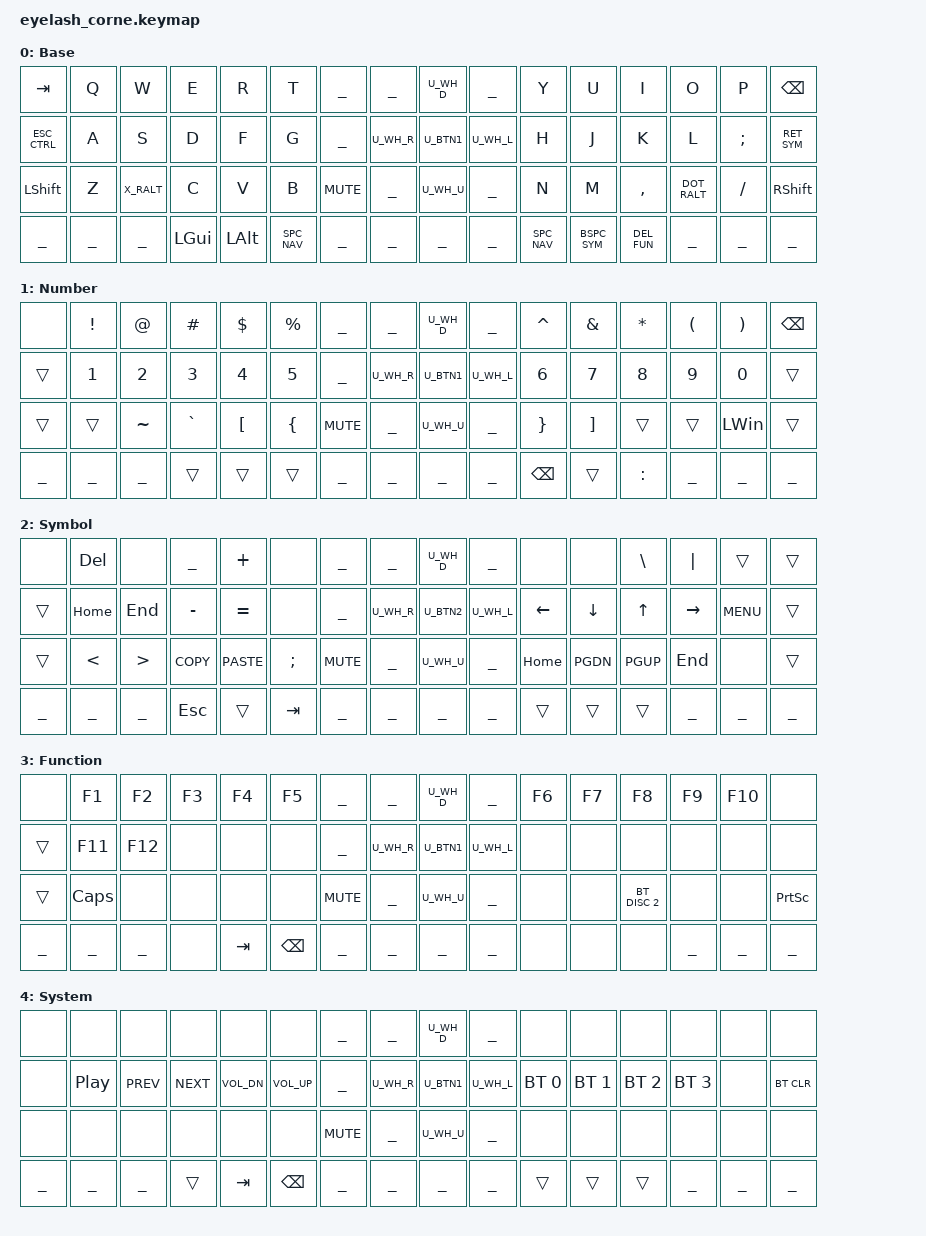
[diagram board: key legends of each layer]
// Example config: https://github.com/manna-harbour/miryoku_zmk?tab=readme-ov-file#example-config-file

#define MIRYOKU_ALPHAS_QWERTY
#define MIRYOKU_TAP_QWERTY
#define MIRYOKU_EXTRA_COLEMAK
#define MIRYOKU_NAV_VI

#define XXX &none

#define ENC_VOL  &inc_dec_kp C_VOLUME_UP C_VOLUME_DOWN
#define CTRL_ESC &mt LEFT_CONTROL ESC

// Make rotary decoder button to mute
// Make joystick to scroll in natural mode, button to click
//

#define MIRYOKU_CLIPBOARD_FUN
#define MIRYOKU_KLUDGE_MOUSEKEYSPR


// #include "../modules/miryoku/miryoku/miryoku.dtsi"
// Adding sensor bindings to the layers for the decoder
//
#include <behaviors.dtsi>
#include <behaviors/mouse_key_press.dtsi>
#include <behaviors/mouse_move.dtsi>
#include <behaviors/mouse_scroll.dtsi>
#include <dt-bindings/zmk/keys.h>
#include <dt-bindings/zmk/bt.h>
#include <dt-bindings/zmk/rgb.h>
#include <dt-bindings/zmk/outputs.h>
#include <dt-bindings/zmk/ext_power.h>

// Define my own miryoku layers that override the default ones
//

// Changes from original
//
// First left thumb -> LGUI instead of Media, Move media to a combo of both thumbs
// Second left thumb -> LALT instead of Nav/space
// Third left thumb -> Nav/space, mouse layer moved to combo
// Remove homerow mods from base layer (some are still in other layers, but not bothering right now)
// Swap semicolon/colon with apostrophe/doble-quote


// Adding an extra layer WIN
// miryoku defines 10 layers, with 0-based index, so next one is number 10
// Adds LALT on right thumb, for Mod+Alt combined modifier
#define U_WIN 10

// Load Miryoku logic
#include "../modules/miryoku/miryoku/miryoku.h"

#include <dt-bindings/zmk/mouse.h>

// empty key block, for better spacing
#define ___ 

// TODO what is LFUN
// TODO what is LBTN
// TODO once LBTN is decided, update Z_BTN, SLASH_BTN

#define LBASE 0
#define LSYM 1 // lower
#define LNAV 2 // raise
#define LFUN 3 // function
#define LSYS 4 // system

#define ESC_CTRL U_MT(LCTRL, ESC)
// #define Z_BTN U_LT(U_BUTTON, Z)
#define Z_BTN &kp Z
#define SLASH_BTN &kp SLASH
#define X_RALT U_MT(RALT, X)
#define DOT_RALT U_MT(RALT, DOT)
#define SPC_NAV U_LT(LNAV, SPACE)
#define BSPC_SYM U_LT(LSYM, BSPC)
#define DEL_FUN U_LT(LFUN, DEL)
#define RET_SYM U_LT(LSYM, RET)

#define BT_SEL_0 &bt BT_SEL 0
#define BT_SEL_1 &bt BT_SEL 1
#define BT_SEL_2 &bt BT_SEL 2
#define BT_SEL_3 &bt BT_SEL 3
#define BT_DIS_2 &bt BT_DISC 2
#define BT_CLEAR &bt BT_CLR

/ {
  keymap {
    compatible = "zmk,keymap";

    base {
      display-name = "Base";
      bindings = <
        &kp TAB   &kp Q    &kp W     &kp E       &kp R        &kp T        ___        ___    U_WH_D ___     &kp Y     &kp U      &kp I      &kp O     &kp P      &kp BSPC  \
        ESC_CTRL  &kp A    &kp S     &kp D       &kp F        &kp G        ___        U_WH_R U_BTN1 U_WH_L  &kp H     &kp J      &kp K      &kp L     &kp SEMI   RET_SYM   \
        &kp LSHFT Z_BTN    X_RALT    &kp C       &kp V        &kp B        &kp C_MUTE ___    U_WH_U ___     &kp N     &kp M      &kp COMMA  DOT_RALT  SLASH_BTN  &kp RSHFT \
        ___       ___      ___       &kp LGUI    &kp LALT     SPC_NAV      ___        ___    ___    ___     SPC_NAV   BSPC_SYM   DEL_FUN    ___       ___        ___       \
      >;
      sensor-bindings = < &inc_dec_kp C_VOLUME_UP C_VOLUME_DOWN >;
    };

    lower { display-name = "Number";
      bindings = <
        XXX       &kp EXCL &kp AT    &kp POUND   &kp DLLR     &kp PRCNT    ___        ___    U_WH_D ___     &kp CARET &kp AMPS   &kp ASTRK  &kp LPAR  &kp RPAR   &kp BSPC  \
        &trans    &kp N1   &kp N2    &kp N3      &kp N4       &kp N5       ___        U_WH_R U_BTN1 U_WH_L  &kp N6    &kp N7     &kp N8     &kp N9    &kp N0     &trans    \
        &trans    &trans   &kp TILDE &kp GRAVE   &kp LBKT     &kp LBRC     &kp C_MUTE ___    U_WH_U ___     &kp RBRC  &kp RBKT   &trans     &trans    &kp LWIN   &trans    \
        ___       ___      ___       &trans      &trans       &trans       ___        ___    ___    ___     &kp BKSP  &trans     &kp COLON  ___       ___        ___       \
      >;
      sensor-bindings = < &inc_dec_kp C_VOLUME_UP C_VOLUME_DOWN >;
    };

    raise {
      display-name = "Symbol";
      bindings = <
        XXX       &kp DEL  XXX       &kp UNDER   &kp PLUS     XXX          ___        ___    U_WH_D ___     XXX       XXX        &kp BSLH   &kp PIPE  &trans     &trans    \
        &trans    &kp HOME &kp END   &kp MINUS   &kp EQUAL    XXX          ___        U_WH_R U_BTN2 U_WH_L  &kp LEFT  &kp DOWN   &kp UP     &kp RIGHT &kp K_MENU &trans    \
        &trans    &kp LT   &kp GT    &kp K_COPY  &kp K_PASTE  &kp SEMI     &kp C_MUTE ___    U_WH_U ___     &kp HOME  &kp PGDN   &kp PGUP   &kp END   XXX        &trans    \
        ___       ___      ___       &kp ESC     &trans       &kp TAB      ___        ___    ___    ___     &trans    &trans     &trans     ___       ___        ___       \
      >;
      sensor-bindings = < &inc_dec_kp C_VOLUME_UP C_VOLUME_DOWN >;
    };

    function {
      display-name = "Function";
      bindings = <
        XXX       &kp F1   &kp F2    &kp F3      &kp F4       &kp F5       ___        ___    U_WH_D ___     &kp F6    &kp F7     &kp F8     &kp F9    &kp F10    XXX       \
        &trans    &kp F11  &kp F12   XXX         XXX          XXX          ___        U_WH_R U_BTN1 U_WH_L  XXX       XXX        XXX        XXX       XXX        XXX       \
        &trans    &kp CAPS XXX       XXX         XXX          XXX          &kp C_MUTE ___    U_WH_U ___     XXX       XXX        BT_DIS_2   XXX       XXX        &kp PSCRN \
        ___       ___      ___       XXX         &kp TAB      &kp BSPC     ___        ___    ___    ___     XXX       XXX        XXX        ___       ___        ___       \
      >;
      sensor-bindings = < &inc_dec_kp C_VOLUME_UP C_VOLUME_DOWN >;
    };

    system {
      display-name = "System";
      bindings = <
        XXX       XXX      XXX        XXX        XXX          XXX          ___        ___    U_WH_D ___     XXX       XXX        XXX        XXX       XXX        XXX       \
        XXX       &kp C_PP &kp C_PREV &kp C_NEXT &kp C_VOL_DN &kp C_VOL_UP ___        U_WH_R U_BTN1 U_WH_L  BT_SEL_0  BT_SEL_1   BT_SEL_2   BT_SEL_3  XXX        BT_CLEAR  \
        XXX       XXX      XXX        XXX        XXX          XXX          &kp C_MUTE ___    U_WH_U ___     XXX       XXX        XXX        XXX       XXX        XXX       \
        ___       ___      ___        &trans     &kp TAB      &kp BSPC     ___        ___    ___    ___     &trans    &trans     &trans     ___       ___        ___       \
      >;
      sensor-bindings = < &inc_dec_kp C_VOLUME_UP C_VOLUME_DOWN >;
    };

//     button {
//       display-name = "Button";
//       bindings = <
//         U_LT(U_NUM, TAB) U_UND  U_CUT  U_CPY  U_PST  U_RDO              ___        ___    U_WH_D ___     U_RDO  U_PST  U_CPY  U_CUT  U_UND  &kp BKSP \
//         U_MT(LCTRL, ESC) &kp LGUI  &kp LALT  &kp LCTRL  &kp LSHFT  U_NU             U_WH_R U_BTN1 U_WH_L  U_NU  &kp LSHFT  &kp LCTRL  &kp LALT  &kp LGUI  U_LT(U_SYM, RET) \
//         &kp LSHFT        U_UND  U_CUT  U_CPY  U_PST  U_RDO  &kp C_MUTE ___    U_WH_U ___     U_RDO  U_PST  U_CPY  U_CUT  U_UND  &kp RSHFT \
//         ___              ___               ___           U_BTN3  U_BTN1  U_BTN2 ___        ___     ___   ___     U_BTN2  U_BTN1  U_BTN3
//       >;
//       sensor-bindings = < &inc_dec_kp C_VOLUME_UP C_VOLUME_DOWN >;
//     };

//     nav {
//       display-name = "Nav";
//       bindings = <
//         U_LT(U_NUM, TAB) &kp LBKT  &kp N7  &kp N8  &kp N9  &kp RBKT              ___        ___    U_WH_D ___     U_RDO  U_PST  U_CPY  U_CUT  U_UND  &kp BKSP \
//         U_MT(LCTRL, ESC) &kp SQT  &kp N4  &kp N5  &kp N6  &kp EQUAL             U_WH_R U_BTN1 U_WH_L  &kp LEFT  &kp DOWN  &kp UP  &kp RIGHT  __caps_word  U_LT(U_SYM, RET) \
//         &kp LSHFT        &kp GRAVE  &kp N1  &kp N2  &kp N3  &kp BSLH  &kp C_MUTE ___    U_WH_U ___     &kp HOME  &kp PG_DN  &kp PG_UP  &kp END  &kp INS  &kp RSHFT \
//         ___              ___               ___           &kp DOT  &kp N0  &kp MINUS ___        ___     ___   ___     &kp RET  &kp BSPC  &kp DEL
//       >;
//       sensor-bindings = < &inc_dec_kp C_VOLUME_UP C_VOLUME_DOWN >;
//     };

//     mouse {
//       display-name = "Mouse";
//       bindings = <
//         U_LT(U_NUM, TAB) U_BOOT  &u_to_U_TAP  &u_to_U_EXTRA  &u_to_U_BASE  U_NA              ___        ___    U_WH_D ___     U_RDO  U_PST  U_CPY  U_CUT  U_UND  &kp BKSP \
//         U_MT(LCTRL, ESC) &kp LGUI  &kp LALT  &kp LCTRL  &kp LSHFT  U_NA             U_WH_R U_BTN1 U_WH_L  U_MS_L  U_MS_D  U_MS_U  U_MS_R  U_NU  U_LT(U_SYM, RET) \
//         &kp LSHFT        U_NA  &kp RALT  &u_to_U_SYM  &u_to_U_MOUSE  U_NA  &kp C_MUTE ___    U_WH_U ___     U_WH_L  U_WH_D  U_WH_U  U_WH_R  U_NU  &kp RSHFT \
//         ___              ___               ___           U_NA  U_NA  U_NA ___        ___     ___   ___     U_BTN2  U_BTN1  U_BTN3
//       >;
//       sensor-bindings = < &inc_dec_kp C_VOLUME_UP C_VOLUME_DOWN >;
//     };

//     media {
//       display-name = "Media";
//       bindings = <
//         U_LT(U_NUM, TAB) U_BOOT  &u_to_U_TAP  &u_to_U_EXTRA  &u_to_U_BASE  U_NA              ___        ___    U_WH_D ___     U_RGB_EFF  U_RGB_HUI  U_RGB_SAI  U_RGB_BRI  U_RGB_TOG  &kp BKSP \
//         U_MT(LCTRL, ESC) &kp LGUI  &kp LALT  &kp LCTRL  &kp LSHFT  U_NA             U_WH_R U_BTN1 U_WH_L  &kp C_PREV  &kp C_VOL_DN  &kp C_VOL_UP  &kp C_NEXT  U_EP_TOG  U_LT(U_SYM, RET) \
//         &kp LSHFT        U_NA  &kp RALT  &u_to_U_FUN  &u_to_U_MEDIA  U_NA  &kp C_MUTE ___    U_WH_U ___     &u_bt_sel_0  &u_bt_sel_1  &u_bt_sel_2  &u_bt_sel_3  &u_out_tog  &kp RSHFT \
//         ___              ___               ___           U_NA  U_NA  U_NA ___        ___     ___   ___     &kp C_STOP  &kp C_PP  &kp C_MUTE
//       >;
//       sensor-bindings = < &inc_dec_kp C_VOLUME_UP C_VOLUME_DOWN >;
//     };

//     num {
//       display-name = "Num";
//       bindings = <
//         U_LT(U_NUM, TAB) &kp LBKT  &kp N7  &kp N8  &kp N9  &kp RBKT              ___        ___    U_WH_D ___     U_NA  &u_to_U_BASE  &u_to_U_EXTRA  &u_to_U_TAP  U_BOOT  &kp BKSP \
//         U_MT(LCTRL, ESC) &kp SQT  &kp N4  &kp N5  &kp N6  &kp EQUAL             U_WH_R U_BTN1 U_WH_L  U_NA  &kp LSHFT  &kp LCTRL  &kp LALT  &kp LGUI  U_LT(U_SYM, RET) \
//         &kp LSHFT        &kp GRAVE  &kp N1  &kp N2  &kp N3  &kp BSLH  &kp C_MUTE ___    U_WH_U ___     U_NA  &u_to_U_NUM  &u_to_U_NAV  &kp RALT  U_NA  &kp RSHFT \
//         ___              ___               ___           &kp DOT  &kp N0  &kp MINUS ___        ___     ___   ___     U_NA  U_NA  U_NA
//       >;
//       sensor-bindings = < &inc_dec_kp C_VOLUME_UP C_VOLUME_DOWN >;
//     };

//     sym {
//       display-name = "Sym";
//       bindings = <
//         U_LT(U_NUM, TAB) &kp LBRC  &kp AMPS  &kp ASTRK  &kp LPAR  &kp RBRC              ___        ___    U_WH_D ___     U_NA  &u_to_U_BASE  &u_to_U_EXTRA  &u_to_U_TAP  U_BOOT  &kp BKSP \
//         U_MT(LCTRL, ESC) &kp DQT  &kp DLLR  &kp PRCNT  &kp CARET  &kp PLUS             U_WH_R U_BTN1 U_WH_L  U_NA  &kp LSHFT  &kp LCTRL  &kp LALT  &kp LGUI  U_LT(U_SYM, RET) \
//         &kp LSHFT        &kp TILDE  &kp EXCL  &kp AT  &kp HASH  &kp PIPE  &kp C_MUTE ___    U_WH_U ___     U_NA  &u_to_U_SYM  &u_to_U_MOUSE  &kp RALT  U_NA  &kp RSHFT \
//         ___              ___               ___           &kp LPAR  &kp RPAR  &kp UNDER ___        ___     ___   ___     U_NA  U_NA  U_NA
//       >;
//       sensor-bindings = < &inc_dec_kp C_VOLUME_UP C_VOLUME_DOWN >;
//     };

//     fun {
//       display-name = "Fun";
//       bindings = <
//         U_LT(U_NUM, TAB) &kp F12  &kp F7  &kp F8  &kp F9  &kp PSCRN              ___        ___    U_WH_D ___     U_NA  &u_to_U_BASE  &u_to_U_EXTRA  &u_to_U_TAP  U_BOOT  &kp BKSP \
//         U_MT(LCTRL, ESC) &kp F11  &kp F4  &kp F5  &kp F6  &kp SLCK             U_WH_R U_BTN1 U_WH_L  U_NA  &kp LSHFT  &kp LCTRL  &kp LALT  &kp LGUI  U_LT(U_SYM, RET) \
//         &kp LSHFT        &kp F10  &kp F1  &kp F2  &kp F3  &kp PAUSE_BREAK  &kp C_MUTE ___    U_WH_U ___     U_NA  &u_to_U_FUN  &u_to_U_MEDIA  &kp RALT  U_NA  &kp RSHFT \
//         ___              ___               ___           &kp K_APP  &kp TAB  &kp SPACE ___        ___     ___   ___     U_NA  U_NA  U_NA
//       >;
//       sensor-bindings = < &inc_dec_kp C_VOLUME_UP C_VOLUME_DOWN >;
//     };

//     WIN {
//       display-name = "Win";
//       bindings = <
// U_LT(U_NUM, TAB)  &kp LG(Q)   &kp LG(N7)  &kp LG(N8)  &kp LG(N9)     &kp LG(PSCRN)              ___        ___    U_WH_D ___     &kp LG(R)   &kp LG(Z)    U_CPY      U_CUT      U_UND         &kp LG(BKSP)
// U_MT(LCTRL, ESC)  &kp LG(A)   &kp LG(N4)  &kp LG(N5)  &kp LG(N6)     &kp LG(SLCK)              U_WH_R U_BTN1 U_WH_L  &kp LG(H)   &kp LG(J)    &kp LG(K)  &kp LG(L)  &u_caps_word  &kp LG(RET)
// &kp LSHFT         &kp LG(N0)  &kp LG(N1)  &kp LG(N2)  &kp LG(N3)     &kp LG(SPACE)  &kp C_MUTE ___    U_WH_U ___     &kp HOME    &kp PG_DN    &kp PG_UP  &kp END    &kp INS       &kp LG(RSHFT)
// ___              ___               ___           U_NA        &kp LG(LALT)   U_NA ___        ___     ___   ___     &kp LG(SPC) &kp LG(BSPC) &kp LG(LALT)
//       >;
//       sensor-bindings = < &inc_dec_kp C_VOLUME_UP C_VOLUME_DOWN >;
//     };

  };
};

#include "../modules/miryoku/miryoku/miryoku_shift_functions.dtsi"

#include "../modules/miryoku/miryoku/miryoku_double_tap_guard.dtsi"
#include "../modules/miryoku/miryoku/miryoku_kludge_mousekeyspr.dtsi"

// #include "../modules/miryoku/miryoku/miryoku_behaviors.dtsi"
// Modifying flavor for behaviors, "balanced" works better for me
/ {
  behaviors {
    u_mt: u_mt {
      compatible = "zmk,behavior-hold-tap";
      #binding-cells = <2>;
      tapping-term-ms = <U_TAPPING_TERM>;
      flavor = "balanced";
      bindings = <&kp>, <&kp>;
    };
    u_lt: u_lt {
      compatible = "zmk,behavior-hold-tap";
      #binding-cells = <2>;
      tapping-term-ms = <U_TAPPING_TERM>;
      flavor = "balanced";
      bindings = <&mo>, <&kp>;
    };
  };
};

// My combos
/ {
    combos {
        compatible = "zmk,combos";
     //        thumbcombos_left_media_layer {
     //            layers = <LBASE LNAV>;
     //            key-positions = <42 43>;
     //            bindings = <&lt LFUN LGUI>;
     //            timeout-ms = <50>;
     //        };
     //        thumbcombos_left_mouse_layer {
     //            layers = <LBASE LNAV>;
     //            key-positions = <43 44>;
     //            bindings = <&lt LSYS LALT>;
     //            timeout-ms = <50>;
     //        };
        // for international characters in us-altgr layout
        /* thumbcombos_right_altgr { */
        /*     layers = <LBASE LNAV>; */
        /*     key-positions = <46 47>; */
        /*     bindings = <&kp RALT>; */
        /*     timeout-ms = <50>; */
        /* }; */
        /**/
        /* esc_j_k { */
        /*     layers = <U_BASE U_NAV>; */
        /*     key-positions = <23 24>; */
        /*     bindings = <&kp ESC>; */
        /*     timeout-ms = <50>; */
        /* }; */
    };
};
